# liliumFP1_application register map
Vendor: Nordic Semiconductor; Series: liliumFP1; File version: 1
CPU: CM33 r0p4, little endian, MPU, FPU, 3 interrupt priority bits, 480 interrupts
Registers are 32-bit, read-write, reset 0x0 unless marked. A register's access mark holds for its fields unless they carry their own. Offsets are from the block's base; [hi:lo] are bit positions; lines under a group give offsets from that group; 'fields as' and 'values as' point back to an identical list.

## GLOBAL_SPIM120_NS — Serial Peripheral Interface Master with EasyDMA 0
Base 0x4F8E6000
Same registers: GLOBAL_SPIM121_NS 0x4F8E7000, GLOBAL_SPIM130_NS 0x4F9A5000, GLOBAL_SPIM131_NS 0x4F9A6000, GLOBAL_SPIM132_NS 0x4F9B5000, GLOBAL_SPIM133_NS 0x4F9B6000, GLOBAL_SPIM134_NS 0x4F9C5000, GLOBAL_SPIM135_NS 0x4F9C6000, GLOBAL_SPIM136_NS 0x4F9D5000, GLOBAL_SPIM137_NS 0x4F9D6000, GLOBAL_SPIM120_S 0x5F8E6000, GLOBAL_SPIM121_S 0x5F8E7000, GLOBAL_SPIM130_S 0x5F9A5000, GLOBAL_SPIM131_S 0x5F9A6000, GLOBAL_SPIM132_S 0x5F9B5000, GLOBAL_SPIM133_S 0x5F9B6000, GLOBAL_SPIM134_S 0x5F9C5000, GLOBAL_SPIM135_S 0x5F9C6000, GLOBAL_SPIM136_S 0x5F9D5000, GLOBAL_SPIM137_S 0x5F9D6000
0x10 TASKS_START wo — Start SPI transaction
  [0] TASKS_START
    1=Trigger task
0x14 TASKS_STOP wo — Stop SPI transaction
  [0] TASKS_STOP
    1=Trigger task
0x1C TASKS_SUSPEND wo — Suspend SPI transaction
  [0] TASKS_SUSPEND
    1=Trigger task
0x20 TASKS_RESUME wo — Resume SPI transaction
  [0] TASKS_RESUME
    1=Trigger task
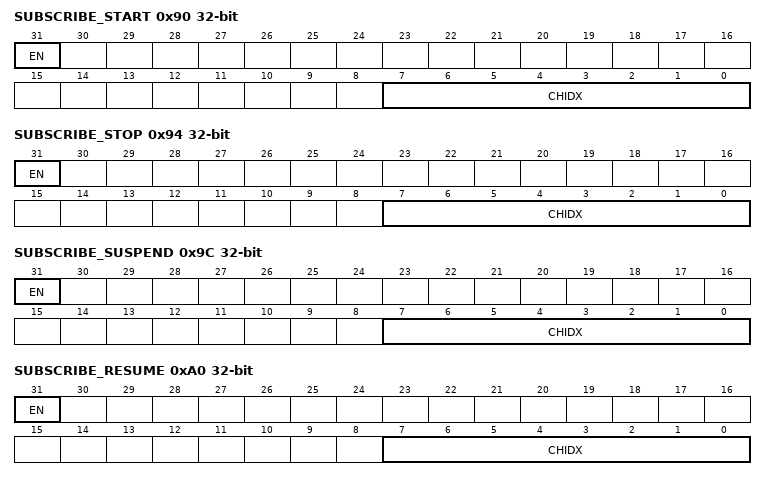
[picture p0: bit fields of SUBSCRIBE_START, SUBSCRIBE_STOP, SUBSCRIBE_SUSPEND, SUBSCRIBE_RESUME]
0x90 SUBSCRIBE_START — Subscribe configuration for task START
  [31] EN
    0=Disabled (Disable subscription); 1=Enabled (Enable subscription)
  [7:0] CHIDX — DPPI channel that task START will subscribe to
0x94 SUBSCRIBE_STOP — Subscribe configuration for task STOP
  [31] EN
    values as SUBSCRIBE_START.EN
  [7:0] CHIDX — DPPI channel that task STOP will subscribe to
0x9C SUBSCRIBE_SUSPEND — Subscribe configuration for task SUSPEND
  [31] EN
    values as SUBSCRIBE_START.EN
  [7:0] CHIDX — DPPI channel that task SUSPEND will subscribe to
0xA0 SUBSCRIBE_RESUME — Subscribe configuration for task RESUME
  [31] EN
    values as SUBSCRIBE_START.EN
  [7:0] CHIDX — DPPI channel that task RESUME will subscribe to
0x104 EVENTS_STOPPED — SPI transaction has stopped
  [0] EVENTS_STOPPED
    0=NotGenerated (Event not generated); 1=Generated (Event generated)
0x110 EVENTS_ENDRX — End of RXD buffer reached
  [0] EVENTS_ENDRX
    values as EVENTS_STOPPED.EVENTS_STOPPED
0x118 EVENTS_END — End of RXD buffer and TXD buffer reached
  [0] EVENTS_END
    values as EVENTS_STOPPED.EVENTS_STOPPED
0x120 EVENTS_ENDTX — End of TXD buffer reached
  [0] EVENTS_ENDTX
    values as EVENTS_STOPPED.EVENTS_STOPPED
0x14C EVENTS_STARTED — Transaction started
  [0] EVENTS_STARTED
    values as EVENTS_STOPPED.EVENTS_STOPPED
0x174 EVENTS_RXBUSERROR — This event is generated if an error occurs during the bus transfer. This event is generated on an AHB / AXI error response.
  [0] EVENTS_RXBUSERROR
    values as EVENTS_STOPPED.EVENTS_STOPPED
0x178 EVENTS_TXBUSERROR — This event is generated if an error occurs during the bus transfer. This event is generated on an AHB / AXI error response.
  [0] EVENTS_TXBUSERROR
    values as EVENTS_STOPPED.EVENTS_STOPPED
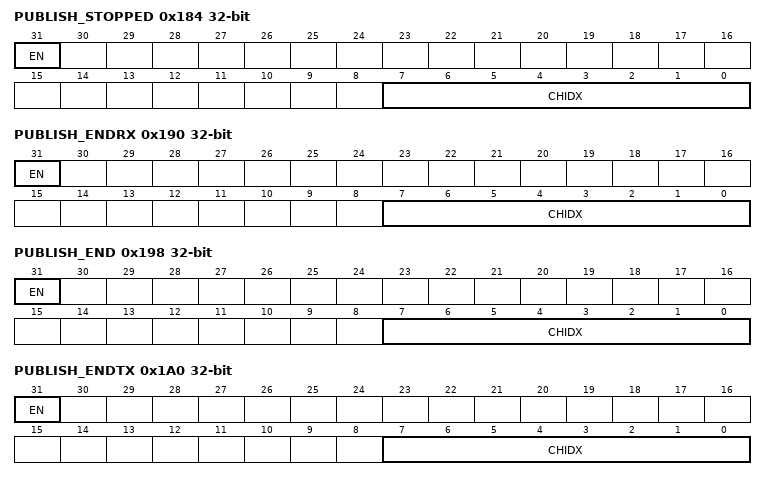
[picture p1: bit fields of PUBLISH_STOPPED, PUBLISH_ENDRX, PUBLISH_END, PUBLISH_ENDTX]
0x184 PUBLISH_STOPPED — Publish configuration for event STOPPED
  [31] EN
    0=Disabled (Disable publishing); 1=Enabled (Enable publishing)
  [7:0] CHIDX — DPPI channel that event STOPPED will publish to
0x190 PUBLISH_ENDRX — Publish configuration for event ENDRX
  [31] EN
    values as PUBLISH_STOPPED.EN
  [7:0] CHIDX — DPPI channel that event ENDRX will publish to
0x198 PUBLISH_END — Publish configuration for event END
  [31] EN
    values as PUBLISH_STOPPED.EN
  [7:0] CHIDX — DPPI channel that event END will publish to
0x1A0 PUBLISH_ENDTX — Publish configuration for event ENDTX
  [31] EN
    values as PUBLISH_STOPPED.EN
  [7:0] CHIDX — DPPI channel that event ENDTX will publish to
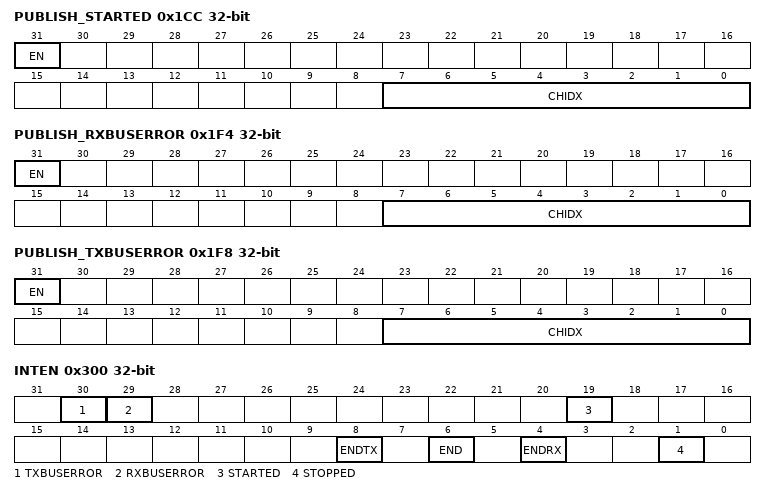
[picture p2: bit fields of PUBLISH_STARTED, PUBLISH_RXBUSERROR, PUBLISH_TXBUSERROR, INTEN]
0x1CC PUBLISH_STARTED — Publish configuration for event STARTED
  [31] EN
    values as PUBLISH_STOPPED.EN
  [7:0] CHIDX — DPPI channel that event STARTED will publish to
0x1F4 PUBLISH_RXBUSERROR — Publish configuration for event RXBUSERROR
  [31] EN
    values as PUBLISH_STOPPED.EN
  [7:0] CHIDX — DPPI channel that event RXBUSERROR will publish to
0x1F8 PUBLISH_TXBUSERROR — Publish configuration for event TXBUSERROR
  [31] EN
    values as PUBLISH_STOPPED.EN
  [7:0] CHIDX — DPPI channel that event TXBUSERROR will publish to
0x200 SHORTS — Shortcuts between local events and tasks
  [17] END_START — Shortcut between event END and task START
    0=Disabled (Disable shortcut); 1=Enabled (Enable shortcut)
0x300 INTEN — Enable or disable interrupt
  [all] fields
    0=Disabled; 1=Enabled
  [30] TXBUSERROR — Enable or disable interrupt for event TXBUSERROR
  [29] RXBUSERROR — Enable or disable interrupt for event RXBUSERROR
  [19] STARTED — Enable or disable interrupt for event STARTED
  [8] ENDTX — Enable or disable interrupt for event ENDTX
  [6] END — Enable or disable interrupt for event END
  [4] ENDRX — Enable or disable interrupt for event ENDRX
  [1] STOPPED — Enable or disable interrupt for event STOPPED
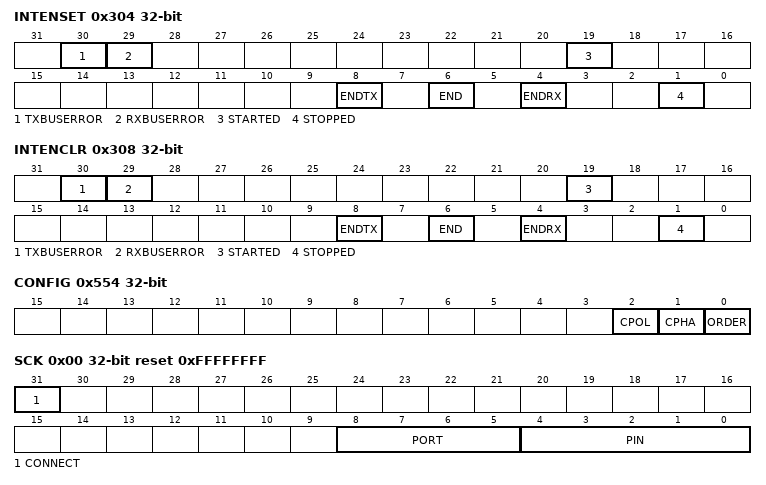
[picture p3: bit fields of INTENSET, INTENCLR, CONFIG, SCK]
0x304 INTENSET — Enable interrupt
  [all] fields
    on read: 0=Disabled (Read: Disabled); 1=Enabled (Read: Enabled) | on write: 1=Set (Enable)
  [30] TXBUSERROR — Write '1' to enable interrupt for event TXBUSERROR
  [29] RXBUSERROR — Write '1' to enable interrupt for event RXBUSERROR
  [19] STARTED — Write '1' to enable interrupt for event STARTED
  [8] ENDTX — Write '1' to enable interrupt for event ENDTX
  [6] END — Write '1' to enable interrupt for event END
  [4] ENDRX — Write '1' to enable interrupt for event ENDRX
  [1] STOPPED — Write '1' to enable interrupt for event STOPPED
0x308 INTENCLR — Disable interrupt
  [all] fields
    on read: 0=Disabled (Read: Disabled); 1=Enabled (Read: Enabled) | on write: 1=Clear (Disable)
  [30] TXBUSERROR — Write '1' to disable interrupt for event TXBUSERROR
  [29] RXBUSERROR — Write '1' to disable interrupt for event RXBUSERROR
  [19] STARTED — Write '1' to disable interrupt for event STARTED
  [8] ENDTX — Write '1' to disable interrupt for event ENDTX
  [6] END — Write '1' to disable interrupt for event END
  [4] ENDRX — Write '1' to disable interrupt for event ENDRX
  [1] STOPPED — Write '1' to disable interrupt for event STOPPED
0x500 ENABLE — Enable SPIM
  [3:0] ENABLE — Enable or disable SPIM
    0=Disabled (Disable SPIM); 7=Enabled (Enable SPIM)
0x518 RXDDATA ro — RXD register
  [7:0] RXD — RX data received. Double buffered.
0x51C TXDDATA — TXD register
  [7:0] TXD — TX data to send. Double buffered.
0x52C PRESCALER reset 0x40 — The prescaler is used to set the SPI frequency.
  [6:0] DIVISOR — Core clock to SCK divisor
0x534 RXD group — RXD EasyDMA channel
  0x00 PTR — Data pointer
  0x04 MAXCNT — Maximum number of bytes in receive buffer
    [15:0] MAXCNT
  0x08 AMOUNT ro — Number of bytes transferred in the last transaction
    [15:0] AMOUNT
  0x0C LIST — EasyDMA list type
    [1:0] LIST — List type
      0=Disabled (Disable EasyDMA list); 1=ArrayList (Use array list)
0x544 TXD group — TXD EasyDMA channel
  0x00 PTR — Data pointer
  0x04 MAXCNT — Number of bytes in transmit buffer
    [15:0] MAXCNT — Maximum number of bytes in transmit buffer
  0x08 AMOUNT ro — Number of bytes transferred in the last transaction
    [15:0] AMOUNT
  0x0C LIST — EasyDMA list type
    fields as RXD.LIST
0x554 CONFIG — Configuration register
  [2] CPOL — Serial clock (SCK) polarity
    0=ActiveHigh; 1=ActiveLow
  [1] CPHA — Serial clock (SCK) phase
    0=Leading (Sample on leading edge of clock, shift serial data on trailing edge); 1=Trailing (Sample on trailing edge of clock, shift serial data on leading edge)
  [0] ORDER — Bit order
    0=MsbFirst (Most significant bit shifted out first); 1=LsbFirst (Least significant bit shifted out first)
0x5B0 DMA group — Unspecified
  0x00 RX group — Unspecified
    0x00 TERMINATEONBUSERROR — Terminate the transaction if a BUSERROR event is detected.
      [0] ENABLE
        0=Disabled; 1=Enabled
    0x04 BUSERRORADDRESS — Address of transaction that generated the last BUSERROR event.
      [31:0] ADDRESS
  0x08 TX group — Unspecified
    0x00 TERMINATEONBUSERROR — Terminate the transaction if a BUSERROR event is detected.
      [0] ENABLE
        0=Disabled; 1=Enabled
    0x04 BUSERRORADDRESS — Address of transaction that generated the last BUSERROR event.
      [31:0] ADDRESS
0x5C0 ORC — Byte transmitted after TXD.MAXCNT bytes have been transmitted in the case when RXD.MAXCNT is greater than TXD.MAXCNT
  [7:0] ORC — Byte transmitted after TXD.MAXCNT bytes have been transmitted in the case when RXD.MAXCNT is greater than TXD.MAXCNT.
0x600 PSEL group — Unspecified
  0x00 SCK reset 0xFFFFFFFF — Pin select for SCK
    [31] CONNECT — Connection
      1=Disconnected; 0=Connected
    [8:5] PORT — Port number
    [4:0] PIN — Pin number
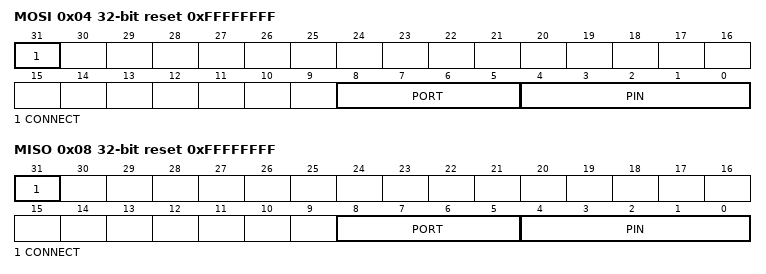
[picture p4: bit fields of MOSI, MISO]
  0x04 MOSI reset 0xFFFFFFFF — Pin select for MOSI signal
    fields as PSEL.SCK
  0x08 MISO reset 0xFFFFFFFF — Pin select for MISO signal
    fields as PSEL.SCK
